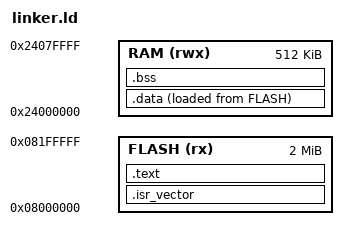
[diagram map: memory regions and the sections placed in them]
ENTRY(Reset_Handler)

_estack = 0x24080000;

MEMORY
{
    FLASH (rx)  : ORIGIN = 0x08000000, LENGTH = 2048K
    RAM   (rwx) : ORIGIN = 0x24000000, LENGTH = 512K
}

SECTIONS
{
    .isr_vector :
    {
        KEEP(*(.isr_vector))
    } > FLASH

    .text :
    {
        *(.text*)
        *(.rodata*)
        _etext = .;
    } > FLASH

    _sidata = LOADADDR(.data);

    .data :
    {
        _sdata = .;
        *(.data*)
        _edata = .;
    } > RAM AT > FLASH

    .bss :
    {
        _sbss = .;
        *(.bss*)
        *(COMMON)
        _ebss = .;
    } > RAM
}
